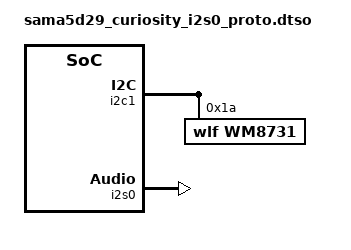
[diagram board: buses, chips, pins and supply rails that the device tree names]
// SPDX-License-Identifier: (GPL-2.0+ OR MIT)
/*
 * Device Tree file for SAMA5D29 Curiosity board
 * overlay blob for I2S with PROTO board. The blob uses i2s0 and i2c1.
 *
 * Copyright (C) 2023 Microchip Technology, Inc. and its subsidiaries
 * Author: Ciprian Abramov <ciprian.abramov@microchip.com>
 *
 */
/dts-v1/;
/plugin/;

#include "sama5d2-pinfunc.h"
#include "dt-bindings/pinctrl/at91.h"

&{/} {
	sound {
		compatible = "mikroe,mikroe-proto";
		model = "wm8731 @ sama5d29-curiosity";
		i2s-controller = <&i2s0>;
		audio-codec = <&wm8731>;
		dai-format = "i2s";
	};
};

&i2c1 {
	#address-cells = <1>;
	#size-cells = <0>;
	wm8731: wm8731@1a {
		#sound-dai-cells = <0>;
		compatible = "wlf,wm8731";
		reg = <0x1a>;
	};
};

&i2s0 {
	pinctrl-names = "default";
	pinctrl-0 = <&pinctrl_i2s0_default>;
	status = "okay";
};

&pioA {
	pinctrl_i2s0_default: i2s0-default {
		pinmux = <PIN_PD19__I2SC0_CK>,
			 <PIN_PD20__I2SC0_MCK>,
			 <PIN_PD21__I2SC0_WS>,
			 <PIN_PD22__I2SC0_DI0>,
			 <PIN_PD23__I2SC0_DO0>;
		bias-disable;
	};
};
